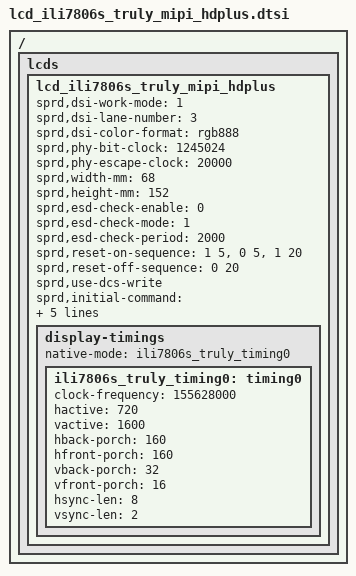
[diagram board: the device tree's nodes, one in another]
/ {
	fragment {
		target-path = "/";
		__overlay__ {
			lcds {
				lcd_ili7806s_truly_mipi_hdplus: lcd_ili7806s_truly_mipi_hdplus {

					sprd,dsi-work-mode = <1>;
					sprd,dsi-lane-number = <3>;
					sprd,dsi-color-format = "rgb888";

					sprd,phy-bit-clock = <1245024>;
					sprd,phy-escape-clock = <20000>;/* kHz */

					sprd,width-mm = <68>;
					sprd,height-mm = <152>;

					sprd,esd-check-enable = <0>;
					sprd,esd-check-mode = <1>;
					sprd,esd-check-period = <2000>;


					sprd,reset-on-sequence = <1 5>, <0 5>, <1 20>;
					sprd,reset-off-sequence = <0 20>;

					sprd,use-dcs-write;
					sprd,initial-command = [
						39 00 00 04 FF 78 07 01
						23 00 00 02 00 42
						23 00 00 02 01 51
						23 00 00 02 02 00
						23 00 00 02 03 9F
						23 00 00 02 04 00
						23 00 00 02 05 00
						23 00 00 02 06 00
						23 00 00 02 07 00
						23 00 00 02 08 89
						23 00 00 02 09 0A
						23 00 00 02 0a 30
						23 00 00 02 0b 01
						23 00 00 02 0C 04
						23 00 00 02 0E 56
						39 00 00 04 FF 78 07 11
						23 00 00 02 00 04
						23 00 00 02 01 56
						23 00 00 02 18 5A
						23 00 00 02 19 00
						23 00 00 02 1A 5A
						23 00 00 02 1B 6A
						23 00 00 02 1C 64
						23 00 00 02 1D 00
						39 00 00 04 FF 78 07 0E
						23 00 00 02 02 0D
						39 00 00 04 FF 78 07 01
						23 00 00 02 31 07
						23 00 00 02 32 07
						23 00 00 02 33 07
						23 00 00 02 34 07
						23 00 00 02 35 07
						23 00 00 02 36 07
						23 00 00 02 37 07
						23 00 00 02 38 40
						23 00 00 02 39 40
						23 00 00 02 3a 02
						23 00 00 02 3b 24
						23 00 00 02 3c 00
						23 00 00 02 3d 00
						23 00 00 02 3e 30
						23 00 00 02 3f 2F
						23 00 00 02 40 2E
						23 00 00 02 41 10
						23 00 00 02 42 12
						23 00 00 02 43 2D
						23 00 00 02 44 41
						23 00 00 02 45 41
						23 00 00 02 46 01
						23 00 00 02 47 24
						23 00 00 02 48 08
						23 00 00 02 49 07
						23 00 00 02 4a 07
						23 00 00 02 4b 07
						23 00 00 02 4c 07
						23 00 00 02 4d 07
						23 00 00 02 4e 07
						23 00 00 02 4f 07
						23 00 00 02 50 40
						23 00 00 02 51 40
						23 00 00 02 52 02
						23 00 00 02 53 24
						23 00 00 02 54 00
						23 00 00 02 55 00
						23 00 00 02 56 30
						23 00 00 02 57 2F
						23 00 00 02 58 2E
						23 00 00 02 59 11
						23 00 00 02 5a 13
						23 00 00 02 5b 2D
						23 00 00 02 5c 41
						23 00 00 02 5d 41
						23 00 00 02 5e 01
						23 00 00 02 5f 24
						23 00 00 02 60 09
						23 00 00 02 61 07
						23 00 00 02 62 07
						23 00 00 02 63 07
						23 00 00 02 64 07
						23 00 00 02 65 07
						23 00 00 02 66 07
						23 00 00 02 67 07
						23 00 00 02 68 40
						23 00 00 02 69 40
						23 00 00 02 6a 02
						23 00 00 02 6b 24
						23 00 00 02 6c 01
						23 00 00 02 6d 01
						23 00 00 02 6e 30
						23 00 00 02 6f 2F
						23 00 00 02 70 2E
						23 00 00 02 71 13
						23 00 00 02 72 11
						23 00 00 02 73 2D
						23 00 00 02 74 41
						23 00 00 02 75 41
						23 00 00 02 76 24
						23 00 00 02 77 00
						23 00 00 02 78 09
						23 00 00 02 79 07
						23 00 00 02 7a 07
						23 00 00 02 7b 07
						23 00 00 02 7c 07
						23 00 00 02 7d 07
						23 00 00 02 7e 07
						23 00 00 02 7f 07
						23 00 00 02 80 40
						23 00 00 02 81 40
						23 00 00 02 82 02
						23 00 00 02 83 24
						23 00 00 02 84 01
						23 00 00 02 85 01
						23 00 00 02 86 30
						23 00 00 02 87 2F
						23 00 00 02 88 2E
						23 00 00 02 89 12
						23 00 00 02 8a 10
						23 00 00 02 8b 2D
						23 00 00 02 8c 41
						23 00 00 02 8d 41
						23 00 00 02 8e 24
						23 00 00 02 8f 00
						23 00 00 02 90 08
						23 00 00 02 92 10
						23 00 00 02 A2 4C
						23 00 00 02 A3 49
						23 00 00 02 A7 10
						23 00 00 02 AE 00
						23 00 00 02 B0 20
						23 00 00 02 B4 05
						23 00 00 02 C0 0C
						23 00 00 02 C6 64
						23 00 00 02 C7 00
						23 00 00 02 D1 02
						23 00 00 02 D2 10
						23 00 00 02 D4 14
						23 00 00 02 D5 01
						23 00 00 02 D7 80
						23 00 00 02 D8 40
						23 00 00 02 D9 04
						23 00 00 02 DF 4A
						23 00 00 02 DE 03
						23 00 00 02 DD 08
						23 00 00 02 E0 00
						23 00 00 02 E1 28
						23 00 00 02 E2 06
						23 00 00 02 E3 31
						23 00 00 02 E4 02
						23 00 00 02 E5 6D
						23 00 00 02 E6 12
						23 00 00 02 E7 0C
						23 00 00 02 ED 56
						39 00 00 04 FF 78 07 02
						23 00 00 02 01 D5
						23 00 00 02 47 00
						23 00 00 02 4F 01
						23 00 00 02 6B 11
						39 00 00 04 FF 78 07 12
						23 00 00 02 10 10
						23 00 00 02 12 08
						23 00 00 02 13 2E
						23 00 00 02 16 08
						23 00 00 02 3A 05
						23 00 00 02 C0 6B
						23 00 00 02 C2 12
						23 00 00 02 C3 20
						39 00 00 04 FF 78 07 04
						23 00 00 02 BD 01
						39 00 00 04 FF 78 07 04
						23 00 00 02 B7 CF
						23 00 00 02 B8 45
						23 00 00 02 BA 74
						39 00 00 04 FF 78 07 05
						23 00 00 02 61 CB
						39 00 00 04 FF 78 07 07
						23 00 00 02 07 4C
						39 00 00 04 FF 78 07 05
						23 00 00 02 72 56
						23 00 00 02 74 56
						23 00 00 02 76 51
						23 00 00 02 7A 51
						23 00 00 02 7B 88
						23 00 00 02 7C 88
						23 00 00 02 AE 29
						23 00 00 02 B1 39
						23 00 00 02 46 58
						23 00 00 02 47 78
						23 00 00 02 B5 58
						23 00 00 02 B7 78
						23 00 00 02 C9 90
						23 00 00 02 56 FF
						39 00 00 04 FF 78 07 06
						23 00 00 02 C0 40
						23 00 00 02 C1 16
						23 00 00 02 C2 FA
						23 00 00 02 C3 06
						23 00 00 02 96 50
						23 00 00 02 13 13
						23 00 00 02 B4 11
						23 00 00 02 B5 13
						39 00 00 04 FF 78 07 08
						39 00 00 20 E0 00 00 15 40 00 7C A9 CD 15 06 32 73 25 A5 EF 2D 2A 67 A8 D0 3F 05 28 51 3F 6C 8C B9 0F D5 D9
						39 00 00 20 E1 00 00 15 40 00 7C A9 CD 15 06 32 73 25 A5 EF 2D 2A 67 A8 D0 3F 05 28 51 3F 6C 8C B9 0F D5 D9
						39 00 00 04 FF 78 07 0B
						23 00 00 02 C0 85
						23 00 00 02 C1 6A
						23 00 00 02 C2 04
						23 00 00 02 C3 04
						23 00 00 02 C4 87
						23 00 00 02 C5 87
						23 00 00 02 D2 43
						23 00 00 02 D3 5C
						23 00 00 02 D4 03
						23 00 00 02 D5 03
						23 00 00 02 D6 54
						23 00 00 02 D7 54
						23 00 00 02 AB E0
						39 00 00 04 FF 78 07 0C
						23 00 00 02 00 22
						23 00 00 02 01 8E
						23 00 00 02 02 23
						23 00 00 02 03 93
						23 00 00 02 04 23
						23 00 00 02 05 93
						23 00 00 02 06 22
						23 00 00 02 07 91
						23 00 00 02 08 22
						23 00 00 02 09 90
						23 00 00 02 0A 22
						23 00 00 02 0B 8D
						23 00 00 02 0C 23
						23 00 00 02 0D 95
						23 00 00 02 0E 22
						23 00 00 02 0F 8C
						23 00 00 02 10 22
						23 00 00 02 11 8F
						23 00 00 02 12 22
						23 00 00 02 13 92
						23 00 00 02 14 23
						23 00 00 02 15 94
						39 00 00 04 FF 78 07 0E
						23 00 00 02 00 A3
						23 00 00 02 04 00
						23 00 00 02 20 07
						23 00 00 02 27 00
						23 00 00 02 29 C8
						23 00 00 02 25 0A
						23 00 00 02 26 AD
						23 00 00 02 2D B8
						23 00 00 02 30 00
						23 00 00 02 21 85
						23 00 00 02 23 85
						23 00 00 02 B0 21
						23 00 00 02 C0 12
						23 00 00 02 05 20
						23 00 00 02 2B 0A
						39 00 00 04 FF 78 07 1E
						23 00 00 02 A2 00
						23 00 00 02 A4 19
						23 00 00 02 A5 30
						23 00 00 02 A6 30
						23 00 00 02 A7 1A
						23 00 00 02 AD 01
						23 00 00 02 00 5C
						23 00 00 02 08 5C
						23 00 00 02 09 5C
						23 00 00 02 0A 10
						23 00 00 02 0C 08
						23 00 00 02 0D 2E
						39 00 00 04 FF 78 07 06
						23 00 00 02 dd 17
						39 00 00 04 FF 78 07 00
						23 78 00 02 11 00
						23 14 00 02 29 00
						23 00 00 02 35 00
						];

					sprd,sleep-in-command = [
						05 0A 00 01 28
						05 78 00 01 10
						];
					sprd,sleep-out-command = [
						05 78 00 01 11
						05 64 00 01 29
						];

					display-timings {
						native-mode = <&ili7806s_truly_timing0>;
						ili7806s_truly_timing0: timing0 {
							clock-frequency = <155628000>;
							hactive = <720>;
							vactive = <1600>;
							hback-porch = <160>;
							hfront-porch = <160>;
							vback-porch = <32>;
							vfront-porch = <16>;
							hsync-len = <8>;
							vsync-len = <2>;

						};
					};
				};
			};
		};
	};
};
